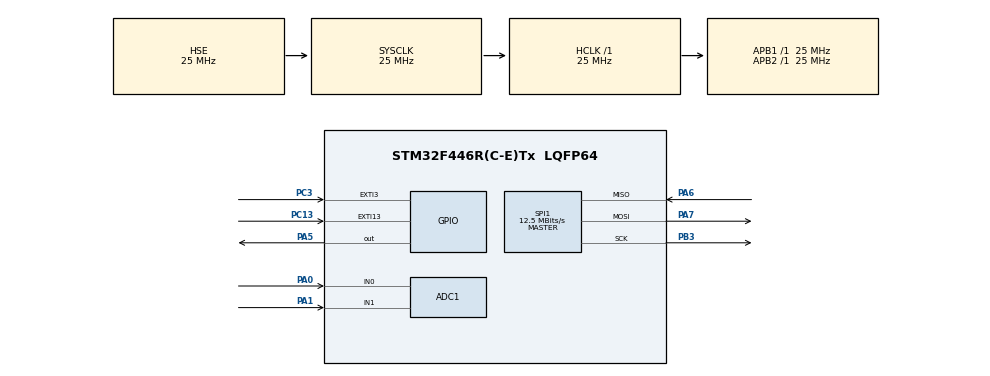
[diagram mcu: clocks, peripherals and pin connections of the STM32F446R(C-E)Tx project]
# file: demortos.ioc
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ADC1.Channel-0\#ChannelRegularConversion=ADC_CHANNEL_TEMPSENSOR
ADC1.NbrOfConversionFlag=1
ADC1.Rank-0\#ChannelRegularConversion=1
ADC1.SamplingTime-0\#ChannelRegularConversion=ADC_SAMPLETIME_3CYCLES
ADC1.master=1
FREERTOS.Events01=myEvent01,Dynamic,NULL;myEvent02,Dynamic,NULL;myEvent03,Dynamic,NULL
FREERTOS.Queues01=myQueue01,16,uint32_t,0,Dynamic,NULL,NULL
FREERTOS.Tasks01=defaultTask,24,128,StartDefaultTask,Default,NULL,Dynamic,NULL,NULL;myTask02,8,128,StartTask02,Default,NULL,Dynamic,NULL,NULL;myTask03,44,128,StartTask03,Default,NULL,Dynamic,NULL,NULL
FREERTOS.Timers01=myTimer01,Callback01,osTimerPeriodic,Default,NULL,Dynamic,NULL
FREERTOS.configENABLE_FPU=1
FREERTOS.configGENERATE_RUN_TIME_STATS=1
FREERTOS.configUSE_NEWLIB_REENTRANT=1
Mcu.Family=STM32F4
Mcu.Name=STM32F446R(C-E)Tx
Mcu.Package=LQFP64
NVIC.ADC_IRQn=true\:5\:0\:false\:false\:true\:true\:true\:true
NVIC.EXTI15_10_IRQn=true\:5\:0\:false\:false\:true\:true\:true\:true
NVIC.EXTI3_IRQn=true\:5\:0\:false\:false\:true\:true\:true\:true
NVIC.PriorityGroup=NVIC_PRIORITYGROUP_4
NVIC.SPI1_IRQn=true\:5\:0\:false\:false\:true\:true\:true\:true
NVIC.TIM1_UP_TIM10_IRQn=true\:5\:0\:false\:false\:true\:true\:true\:true
NVIC.TIM2_IRQn=true\:0\:0\:false\:false\:true\:false\:false\:true
NVIC.TIM4_IRQn=true\:5\:0\:false\:false\:true\:true\:true\:true
NVIC.TimeBase=TIM2_IRQn
NVIC.TimeBaseIP=TIM2
PA0-WKUP.Signal=ADCx_IN0
PA1.Signal=ADCx_IN1
PA5.Signal=GPIO_Output
PA6.Mode=Full_Duplex_Master
PA6.Signal=SPI1_MISO
PA7.Mode=Full_Duplex_Master
PA7.Signal=SPI1_MOSI
PB3.Mode=Full_Duplex_Master
PB3.Signal=SPI1_SCK
PC13.Signal=GPXTI13
PC3.Signal=GPXTI3
PH0-OSC_IN.Mode=HSE-External-Clock-Source
PH0-OSC_IN.Signal=RCC_OSC_IN
PH1-OSC_OUT.Mode=HSE-External-Clock-Source
PH1-OSC_OUT.Signal=RCC_OSC_OUT
ProjectManager.HeapSize=0x200
ProjectManager.StackSize=0x400
ProjectManager.TargetToolchain=STM32CubeIDE
RCC.AHBFreq_Value=25000000
RCC.APB1Freq_Value=25000000
RCC.APB1TimFreq_Value=25000000
RCC.APB2Freq_Value=25000000
RCC.APB2TimFreq_Value=25000000
RCC.CortexFreq_Value=25000000
RCC.HCLKFreq_Value=25000000
RCC.SYSCLKFreq_VALUE=25000000
RCC.SYSCLKSource=RCC_SYSCLKSOURCE_HSE
RCC.USBFreq_Value=96000000
RCC.VCOOutputFreq_Value=192000000
SH.ADCx_IN0.0=ADC1_IN0,IN0
SH.ADCx_IN1.0=ADC1_IN1,IN1
SPI1.BaudRatePrescaler=SPI_BAUDRATEPRESCALER_2
SPI1.CalculateBaudRate=12.5 MBits/s
SPI1.Direction=SPI_DIRECTION_2LINES
SPI1.Mode=SPI_MODE_MASTER
SPI1.VirtualType=VM_MASTER
VP_ADC1_TempSens_Input.Mode=IN-TempSens
VP_FATFS_VS_Generic.Mode=User_defined
VP_FREERTOS_VS_CMSIS_V2.Mode=CMSIS_V2
VP_SYS_VS_tim2.Mode=TIM2
VP_TIM1_VS_ClockSourceINT.Mode=Internal
VP_TIM4_VS_ClockSourceINT.Mode=Internal
board=custom

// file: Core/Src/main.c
/* USER CODE BEGIN Header */
/**
  ******************************************************************************
  * @file           : main.c
  * @brief          : Main program body
  ******************************************************************************
  * @attention
  *
  * <h2><center>&copy; Copyright (c) 2021 STMicroelectronics.
  * All rights reserved.</center></h2>
  *
  * This software component is licensed by ST under BSD 3-Clause license,
  * the "License"; You may not use this file except in compliance with the
  * License. You may obtain a copy of the License at:
  *                        opensource.org/licenses/BSD-3-Clause
  *
  ******************************************************************************
  */
/* USER CODE END Header */
#include "main.h"
#include "cmsis_os.h"
#include "fatfs.h"

/* USER CODE BEGIN Includes */
#include "queue.h"
#include "task.h"
/* USER CODE END Includes */

ADC_HandleTypeDef hadc1;

SPI_HandleTypeDef hspi1;

TIM_HandleTypeDef htim1;
TIM_HandleTypeDef htim4;

/* Definitions for defaultTask */
osThreadId_t defaultTaskHandle;
const osThreadAttr_t defaultTask_attributes = {
  .name = "defaultTask",
  .stack_size = 128 * 4,
  .priority = (osPriority_t) osPriorityNormal,
};
/* Definitions for myTask02 */
osThreadId_t myTask02Handle;
const osThreadAttr_t myTask02_attributes = {
  .name = "myTask02",
  .stack_size = 128 * 4,
  .priority = (osPriority_t) osPriorityLow,
};
/* Definitions for myTask03 */
osThreadId_t myTask03Handle;
const osThreadAttr_t myTask03_attributes = {
  .name = "myTask03",
  .stack_size = 128 * 4,
  .priority = (osPriority_t) osPriorityHigh4,
};
/* Definitions for myQueue01 */
osMessageQueueId_t myQueue01Handle;
const osMessageQueueAttr_t myQueue01_attributes = {
  .name = "myQueue01"
};
/* Definitions for myTimer01 */
osTimerId_t myTimer01Handle;
const osTimerAttr_t myTimer01_attributes = {
  .name = "myTimer01"
};
/* Definitions for myEvent01 */
osEventFlagsId_t myEvent01Handle;
const osEventFlagsAttr_t myEvent01_attributes = {
  .name = "myEvent01"
};
/* Definitions for myEvent02 */
osEventFlagsId_t myEvent02Handle;
const osEventFlagsAttr_t myEvent02_attributes = {
  .name = "myEvent02"
};
/* Definitions for myEvent03 */
osEventFlagsId_t myEvent03Handle;
const osEventFlagsAttr_t myEvent03_attributes = {
  .name = "myEvent03"
};

void SystemClock_Config(void);
static void MX_GPIO_Init(void);
static void MX_ADC1_Init(void);
static void MX_SPI1_Init(void);
static void MX_TIM1_Init(void);
static void MX_TIM4_Init(void);
void StartDefaultTask(void *argument);
void StartTask02(void *argument);
void StartTask03(void *argument);
void Callback01(void *argument);

int main(void)
{

  /* MCU Configuration--------------------------------------------------------*/

  /* Reset of all peripherals, Initializes the Flash interface and the Systick. */
  HAL_Init();

  /* Configure the system clock */
  SystemClock_Config();

  /* Initialize all configured peripherals */
  MX_GPIO_Init();
  MX_ADC1_Init();
  MX_SPI1_Init();
  MX_FATFS_Init();
  MX_TIM1_Init();
  MX_TIM4_Init();

  /* Init scheduler */
  osKernelInitialize();

  /* Create the timer(s) */
  /* creation of myTimer01 */
  myTimer01Handle = osTimerNew(Callback01, osTimerPeriodic, NULL, &myTimer01_attributes);

  /* Create the queue(s) */
  /* creation of myQueue01 */
  myQueue01Handle = osMessageQueueNew (16, sizeof(uint32_t), &myQueue01_attributes);

  /* Create the thread(s) */
  /* creation of defaultTask */
  defaultTaskHandle = osThreadNew(StartDefaultTask, NULL, &defaultTask_attributes);

  /* creation of myTask02 */
  myTask02Handle = osThreadNew(StartTask02, NULL, &myTask02_attributes);

  /* creation of myTask03 */
  myTask03Handle = osThreadNew(StartTask03, NULL, &myTask03_attributes);

  /* Create the event(s) */
  /* creation of myEvent01 */
  myEvent01Handle = osEventFlagsNew(&myEvent01_attributes);

  /* creation of myEvent02 */
  myEvent02Handle = osEventFlagsNew(&myEvent02_attributes);

  /* creation of myEvent03 */
  myEvent03Handle = osEventFlagsNew(&myEvent03_attributes);

  /* Start scheduler */
  osKernelStart();

  /* We should never get here as control is now taken by the scheduler */
  /* Infinite loop */
  while (1)
  {

  }
}

void SystemClock_Config(void)
{
  RCC_OscInitTypeDef RCC_OscInitStruct = {0};
  RCC_ClkInitTypeDef RCC_ClkInitStruct = {0};

  /** Configure the main internal regulator output voltage
  */
  __HAL_RCC_PWR_CLK_ENABLE();
  __HAL_PWR_VOLTAGESCALING_CONFIG(PWR_REGULATOR_VOLTAGE_SCALE3);
  /** Initializes the RCC Oscillators according to the specified parameters
  * in the RCC_OscInitTypeDef structure.
  */
  RCC_OscInitStruct.OscillatorType = RCC_OSCILLATORTYPE_HSE;
  RCC_OscInitStruct.HSEState = RCC_HSE_BYPASS;
  RCC_OscInitStruct.PLL.PLLState = RCC_PLL_NONE;
  if (HAL_RCC_OscConfig(&RCC_OscInitStruct) != HAL_OK)
  {
    Error_Handler();
  }
  /** Initializes the CPU, AHB and APB buses clocks
  */
  RCC_ClkInitStruct.ClockType = RCC_CLOCKTYPE_HCLK|RCC_CLOCKTYPE_SYSCLK
                              |RCC_CLOCKTYPE_PCLK1|RCC_CLOCKTYPE_PCLK2;
  RCC_ClkInitStruct.SYSCLKSource = RCC_SYSCLKSOURCE_HSE;
  RCC_ClkInitStruct.AHBCLKDivider = RCC_SYSCLK_DIV1;
  RCC_ClkInitStruct.APB1CLKDivider = RCC_HCLK_DIV1;
  RCC_ClkInitStruct.APB2CLKDivider = RCC_HCLK_DIV1;

  if (HAL_RCC_ClockConfig(&RCC_ClkInitStruct, FLASH_LATENCY_0) != HAL_OK)
  {
    Error_Handler();
  }
}

static void MX_ADC1_Init(void)
{

  ADC_ChannelConfTypeDef sConfig = {0};

  /** Configure the global features of the ADC (Clock, Resolution, Data Alignment and number of conversion)
  */
  hadc1.Instance = ADC1;
  hadc1.Init.ClockPrescaler = ADC_CLOCK_SYNC_PCLK_DIV2;
  hadc1.Init.Resolution = ADC_RESOLUTION_12B;
  hadc1.Init.ScanConvMode = DISABLE;
  hadc1.Init.ContinuousConvMode = DISABLE;
  hadc1.Init.DiscontinuousConvMode = DISABLE;
  hadc1.Init.ExternalTrigConvEdge = ADC_EXTERNALTRIGCONVEDGE_NONE;
  hadc1.Init.ExternalTrigConv = ADC_SOFTWARE_START;
  hadc1.Init.DataAlign = ADC_DATAALIGN_RIGHT;
  hadc1.Init.NbrOfConversion = 1;
  hadc1.Init.DMAContinuousRequests = DISABLE;
  hadc1.Init.EOCSelection = ADC_EOC_SINGLE_CONV;
  if (HAL_ADC_Init(&hadc1) != HAL_OK)
  {
    Error_Handler();
  }
  /** Configure for the selected ADC regular channel its corresponding rank in the sequencer and its sample time.
  */
  sConfig.Channel = ADC_CHANNEL_TEMPSENSOR;
  sConfig.Rank = 1;
  sConfig.SamplingTime = ADC_SAMPLETIME_3CYCLES;
  if (HAL_ADC_ConfigChannel(&hadc1, &sConfig) != HAL_OK)
  {
    Error_Handler();
  }

}

static void MX_SPI1_Init(void)
{

  /* SPI1 parameter configuration*/
  hspi1.Instance = SPI1;
  hspi1.Init.Mode = SPI_MODE_MASTER;
  hspi1.Init.Direction = SPI_DIRECTION_2LINES;
  hspi1.Init.DataSize = SPI_DATASIZE_8BIT;
  hspi1.Init.CLKPolarity = SPI_POLARITY_LOW;
  hspi1.Init.CLKPhase = SPI_PHASE_1EDGE;
  hspi1.Init.NSS = SPI_NSS_SOFT;
  hspi1.Init.BaudRatePrescaler = SPI_BAUDRATEPRESCALER_2;
  hspi1.Init.FirstBit = SPI_FIRSTBIT_MSB;
  hspi1.Init.TIMode = SPI_TIMODE_DISABLE;
  hspi1.Init.CRCCalculation = SPI_CRCCALCULATION_DISABLE;
  hspi1.Init.CRCPolynomial = 10;
  if (HAL_SPI_Init(&hspi1) != HAL_OK)
  {
    Error_Handler();
  }

}

static void MX_TIM1_Init(void)
{

  TIM_ClockConfigTypeDef sClockSourceConfig = {0};
  TIM_MasterConfigTypeDef sMasterConfig = {0};

  htim1.Instance = TIM1;
  htim1.Init.Prescaler = 0;
  htim1.Init.CounterMode = TIM_COUNTERMODE_UP;
  htim1.Init.Period = 65535;
  htim1.Init.ClockDivision = TIM_CLOCKDIVISION_DIV1;
  htim1.Init.RepetitionCounter = 0;
  htim1.Init.AutoReloadPreload = TIM_AUTORELOAD_PRELOAD_DISABLE;
  if (HAL_TIM_Base_Init(&htim1) != HAL_OK)
  {
    Error_Handler();
  }
  sClockSourceConfig.ClockSource = TIM_CLOCKSOURCE_INTERNAL;
  if (HAL_TIM_ConfigClockSource(&htim1, &sClockSourceConfig) != HAL_OK)
  {
    Error_Handler();
  }
  sMasterConfig.MasterOutputTrigger = TIM_TRGO_RESET;
  sMasterConfig.MasterSlaveMode = TIM_MASTERSLAVEMODE_DISABLE;
  if (HAL_TIMEx_MasterConfigSynchronization(&htim1, &sMasterConfig) != HAL_OK)
  {
    Error_Handler();
  }

}

static void MX_TIM4_Init(void)
{

  TIM_ClockConfigTypeDef sClockSourceConfig = {0};
  TIM_MasterConfigTypeDef sMasterConfig = {0};

  htim4.Instance = TIM4;
  htim4.Init.Prescaler = 0;
  htim4.Init.CounterMode = TIM_COUNTERMODE_UP;
  htim4.Init.Period = 65535;
  htim4.Init.ClockDivision = TIM_CLOCKDIVISION_DIV1;
  htim4.Init.AutoReloadPreload = TIM_AUTORELOAD_PRELOAD_DISABLE;
  if (HAL_TIM_Base_Init(&htim4) != HAL_OK)
  {
    Error_Handler();
  }
  sClockSourceConfig.ClockSource = TIM_CLOCKSOURCE_INTERNAL;
  if (HAL_TIM_ConfigClockSource(&htim4, &sClockSourceConfig) != HAL_OK)
  {
    Error_Handler();
  }
  sMasterConfig.MasterOutputTrigger = TIM_TRGO_RESET;
  sMasterConfig.MasterSlaveMode = TIM_MASTERSLAVEMODE_DISABLE;
  if (HAL_TIMEx_MasterConfigSynchronization(&htim4, &sMasterConfig) != HAL_OK)
  {
    Error_Handler();
  }

}

static void MX_GPIO_Init(void)
{
  GPIO_InitTypeDef GPIO_InitStruct = {0};

  /* GPIO Ports Clock Enable */
  __HAL_RCC_GPIOC_CLK_ENABLE();
  __HAL_RCC_GPIOH_CLK_ENABLE();
  __HAL_RCC_GPIOA_CLK_ENABLE();
  __HAL_RCC_GPIOB_CLK_ENABLE();

  /*Configure GPIO pin Output Level */
  HAL_GPIO_WritePin(GPIOA, GPIO_PIN_5, GPIO_PIN_RESET);

  /*Configure GPIO pins : PC13 PC3 */
  GPIO_InitStruct.Pin = GPIO_PIN_13|GPIO_PIN_3;
  GPIO_InitStruct.Mode = GPIO_MODE_IT_RISING;
  GPIO_InitStruct.Pull = GPIO_NOPULL;
  HAL_GPIO_Init(GPIOC, &GPIO_InitStruct);

  /*Configure GPIO pin : PA5 */
  GPIO_InitStruct.Pin = GPIO_PIN_5;
  GPIO_InitStruct.Mode = GPIO_MODE_OUTPUT_PP;
  GPIO_InitStruct.Pull = GPIO_NOPULL;
  GPIO_InitStruct.Speed = GPIO_SPEED_FREQ_LOW;
  HAL_GPIO_Init(GPIOA, &GPIO_InitStruct);

  /* EXTI interrupt init*/
  HAL_NVIC_SetPriority(EXTI3_IRQn, 5, 0);
  HAL_NVIC_EnableIRQ(EXTI3_IRQn);

  HAL_NVIC_SetPriority(EXTI15_10_IRQn, 5, 0);
  HAL_NVIC_EnableIRQ(EXTI15_10_IRQn);

}

void StartDefaultTask(void *argument)
{
  for(;;)
  {
    osDelay(1);
  }
}

void StartTask02(void *argument)
{
  /* USER CODE BEGIN StartTask02 */
  /* Infinite loop */
  for(;;)
  {
   uint8_t curval = 0;
   xQueueReceive(myQueue01Handle, &curval, portMAX_DELAY); /* wait for 100 ticks */
   if (curval > 10)
   {
	  /* notify Task3 that an alarm has been issued */
	  xTaskNotifyGive(myTask03Handle);

   }
   else
   {
	   /* misra empty */
   }
    //osDelay(2);
  }
  /* USER CODE END StartTask02 */
}

void StartTask03(void *argument)
{
  /* USER CODE BEGIN StartTask03 */
  /* Infinite loop */
  for(;;)
  {
	/* this handles when the alarm went off */
	if (ulTaskNotifyTake(pdTRUE, portMAX_DELAY))
	{
		HAL_GPIO_TogglePin(GPIOA, GPIO_PIN_5);
	}
	osDelay(5);
  }
  /* USER CODE END StartTask03 */
}

/* Callback01 function */
void Callback01(void *argument)
{
}

void HAL_TIM_PeriodElapsedCallback(TIM_HandleTypeDef *htim)
{
  if (htim->Instance == TIM2) {
    HAL_IncTick();
  }
}

void Error_Handler(void)
{
  __disable_irq();
  while (1)
  {
  }
}

/************************ (C) COPYRIGHT STMicroelectronics *****END OF FILE****/
